# AVR128DB28 register map
Vendor: Atmel; File version: 1.0
CPU: other r0p0, little endian, no MPU, no FPU, 4 interrupt priority bits
Registers are 8-bit, read-write, reset 0x0 unless marked. A register's access mark holds for its fields unless they carry their own. Offsets are from the block's base; [hi:lo] are bit positions; {n}, {i} and the like mark numbered series.

## CPU
Base 0x00800034
0x00 CCP — Configuration Change Protection
  [7:0] CCP — CCP signature
    157=SPM (SPM Instruction Protection); 216=IOREG (IO Register Protection)
0x07 RAMPZ — Extended Z-pointer Register
  [0] RAMPZ — Extended Z-Pointer Address bits
0x09 SP 16-bit (reset mask 0xFF) — Stack Pointer
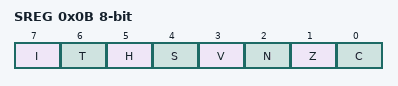
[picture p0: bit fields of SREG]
0x0B SREG — Status Register
  [7] I — Global Interrupt Enable Flag
  [6] T — Transfer Bit
  [5] H — Half Carry Flag
  [4] S — N Exclusive Or V Flag
  [3] V — Two's Complement Overflow Flag
  [2] N — Negative Flag
  [1] Z — Zero Flag
  [0] C — Carry Flag

## CPUINT — Interrupt Controller
Base 0x00800110
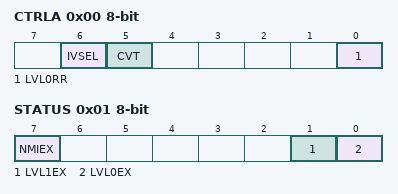
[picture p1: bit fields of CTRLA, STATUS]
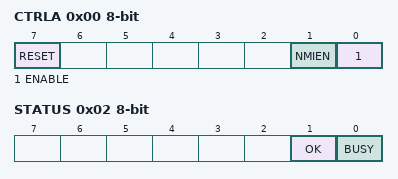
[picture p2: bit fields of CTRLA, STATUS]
0x00 CTRLA — Control A
  [6] IVSEL — Interrupt Vector Select
  [5] CVT — Compact Vector Table
  [0] LVL0RR — Round-robin Scheduling Enable
0x01 STATUS ro
  [7] NMIEX — Non-maskable Interrupt Executing
  [1] LVL1EX — Level 1 Interrupt Executing
  [0] LVL0EX — Level 0 Interrupt Executing
0x02 LVL0PRI — Interrupt Level 0 Priority
  [7:0] LVL0PRI — Interrupt Level Priority
0x03 LVL1VEC — Interrupt Level 1 Priority Vector
  [7:0] LVL1VEC — Interrupt Vector with High Priority

## CRCSCAN
Base 0x00800120
0x00 CTRLA — Control A
  [7] RESET — Reset CRC scan
  [1] NMIEN — Enable NMI Trigger
  [0] ENABLE — Enable CRC scan
0x01 CTRLB — Control B
  [1:0] SRC — CRC Source
    0=FLASH (CRC on entire flash); 1=BOOTAPP (CRC on boot and appl section of flash); 2=BOOT (CRC on boot section of flash)
0x02 STATUS ro
  [1] OK — CRC Ok
  [0] BUSY — CRC Busy

## DAC0 — Digital to Analog Converter
Base 0x008006A0
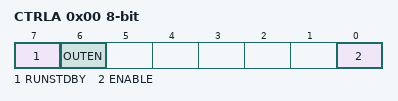
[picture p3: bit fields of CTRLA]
0x00 CTRLA — Control Register A
  [7] RUNSTDBY — Run in Standby Mode
  [6] OUTEN — Output Buffer Enable
  [0] ENABLE — DAC Enable
0x02 DATA 16-bit (reset mask 0xFF)
  [15:6] DATA

## GPR — General Purpose Registers
Base 0x0080001C
{0x0+i} GPR{i} (i=0..3) — General Purpose Register {i}

## LOCK — Lockbits
Base 0x00801040
0x00 KEY 32-bit (reset mask 0xFF) — Lock Key Bits
  [31:0] KEY — Lock Key
    0x5CC5C55C=NOLOCK (No locks); 0xA33A3AA3=RWLOCK (Read and write lock)

## MVIO — Multi-Voltage I/O
Base 0x008000C0
0x00 INTCTRL — Interrupt Control
  [0] VDDIO2IE — VDDIO2 Interrupt Enable
0x01 INTFLAGS — Interrupt Flags
  [0] VDDIO2IF — VDDIO2 Interrupt Flag
0x02 STATUS ro
  [0] VDDIO2S — VDDIO2 Status

## NVMCTRL — Non-volatile Memory Controller
Base 0x00801000
0x00 CTRLA — Control A
  [6:0] CMD — Command
    0=NONE (No Command); 1=NOOP (No Operation); 2=FLWR (Flash Write); 8=FLPER (Flash Page Erase); 9=FLMPER2 (Flash Multi-Page Erase 2 pages); 10=FLMPER4 (Flash Multi-Page Erase 4 pages); 11=FLMPER8 (Flash Multi-Page Erase 8 pages); 12=FLMPER16 (Flash Multi-Page Erase 16 pages); 13=FLMPER32 (Flash Multi-Page Erase 32 pages); 18=EEWR (EEPROM Write); 19=EEERWR (EEPROM Erase and Write); 24=EEBER (EEPROM Byte Erase); 25=EEMBER2 (EEPROM Multi-Byte Erase 2 bytes); 26=EEMBER4 (EEPROM Multi-Byte Erase 4 bytes); 27=EEMBER8 (EEPROM Multi-Byte Erase 8 bytes); 28=EEMBER16 (EEPROM Multi-Byte Erase 16 bytes); 29=EEMBER32 (EEPROM Multi-Byte Erase 32 bytes); 32=CHER (Chip Erase Command); 48=EECHER (EEPROM Erase Command)
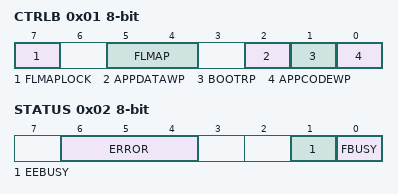
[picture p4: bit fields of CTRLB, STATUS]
0x01 CTRLB — Control B
  [7] FLMAPLOCK — Flash Mapping Lock
  [5:4] FLMAP — Flash Mapping in Data space
    {v}=SECTION{v} (Flash section {v}) (v=0..3)
  [2] APPDATAWP — Application Data Write Protect
  [1] BOOTRP — Boot Read Protect
  [0] APPCODEWP — Application Code Write Protect
0x02 STATUS ro
  [6:4] ERROR — Write error
    0=NOERROR; 1=ILLEGALCMD (Write command not selected); 2=ILLEGALSADDR (Write to section not allowed); 3=DOUBLESELECT (Selecting new write command while write command already seleted); 4=ONGOINGPROG (Starting a new programming operation before previous is completed)
  [1] EEBUSY — EEPROM busy
  [0] FBUSY — Flash busy
0x03 INTCTRL — Interrupt Control
  [0] EEREADY — EEPROM Ready
0x04 INTFLAGS — Interrupt Flags
  [0] EEREADY — EEPROM Ready
0x06 DATA 16-bit (reset mask 0xFF)
0x08 ADDR 32-bit (reset mask 0xFF) — Address
